# EVE4_L2_FNOC register map
Vendor: Texas Instruments
Peripheral module from a debugger description file (folder TDA2Px).
Registers are 32-bit, read-only, reset 0x0 unless marked. A register's access mark holds for its fields unless they carry their own. Offsets are as the file gives them; lines under a group give offsets from that group; [hi:lo] are bit positions; {n}, {i} and the like mark numbered series; 'fields as' and 'values as' point back to an identical list; <NAME> marks a mode.

## EVE4_L2_FNOC
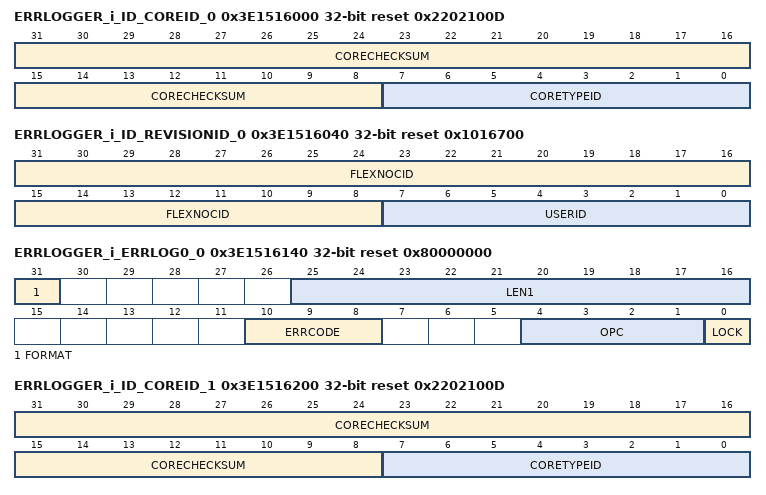
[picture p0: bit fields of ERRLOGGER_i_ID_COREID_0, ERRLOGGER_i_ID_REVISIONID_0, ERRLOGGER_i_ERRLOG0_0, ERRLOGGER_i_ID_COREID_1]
0x3E1516000 ERRLOGGER_i_ID_COREID_0 reset 0x2202100D
  [31:8] CORECHECKSUM — Field containing a checksum of the parameters of the IP.
  [7:0] CORETYPEID — Field identifying the type of IP.
0x3E1516040 ERRLOGGER_i_ID_REVISIONID_0 reset 0x1016700
  [31:8] FLEXNOCID — Field containing the build revision of the software used to generate the IP HDL code.
  [7:0] USERID — Field containing a user defined value, not used anywhere inside the IP itself.
0x3E1516080 ERRLOGGER_i_FAULTEN_0 access per field
  [0] FAULTEN rw — Enable Fault output
0x3E15160C0 ERRLOGGER_i_ERRVLD_0
  [0] ERRVLD — Error logged Valid
0x3E1516100 ERRLOGGER_i_ERRCLR_0 access per field
  [0] ERRCLR rw — Clr ErrVld status
0x3E1516140 ERRLOGGER_i_ERRLOG0_0 reset 0x80000000 — Header: Lock, Opcode, Len1, ErrCode values
  [31] FORMAT — Format of ErrLog0 register
  [25:16] LEN1 — Header: Len1 value
  [10:8] ERRCODE — Header: Error Code value
  [4:1] OPC — Header: Opcode value
  [0] LOCK — Header: Lock bit value
0x3E1516180 ERRLOGGER_i_ERRLOG1_0
  [13:0] ERRLOG1 — Header: RouteId lsb value
0x3E1516200 ERRLOGGER_i_ID_COREID_1 reset 0x2202100D
  fields as ERRLOGGER_i_ID_COREID_0
0x3E1516200 ERRLOGGER_i_ERRLOG3_0
  [31:0] ERRLOG3 — Header: Addr lsb value
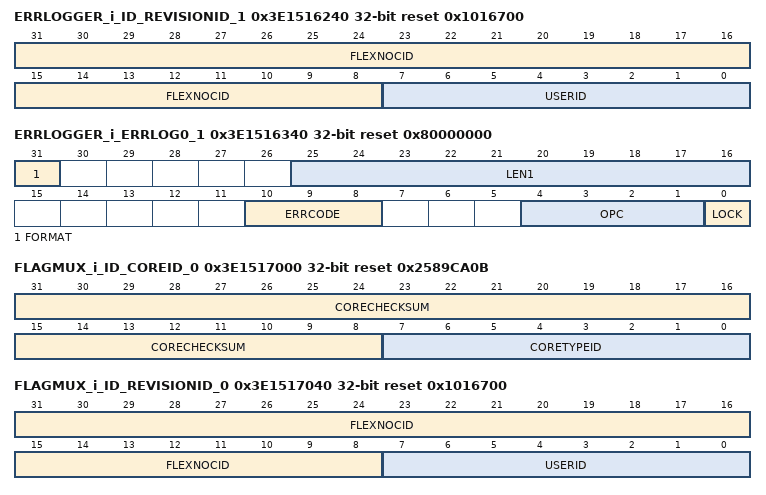
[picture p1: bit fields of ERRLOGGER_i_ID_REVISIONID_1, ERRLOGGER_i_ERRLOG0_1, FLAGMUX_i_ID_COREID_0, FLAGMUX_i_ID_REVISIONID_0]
0x3E1516240 ERRLOGGER_i_ID_REVISIONID_1 reset 0x1016700
  fields as ERRLOGGER_i_ID_REVISIONID_0
0x3E1516280 ERRLOGGER_i_FAULTEN_1 access per field
  [0] FAULTEN rw — Enable Fault output
0x3E1516280 ERRLOGGER_i_ERRLOG5_0
  [16:0] ERRLOG5 — Header: User lsb value
0x3E15162C0 ERRLOGGER_i_ERRVLD_1
  [0] ERRVLD — Error logged Valid
0x3E1516300 ERRLOGGER_i_ERRCLR_1 access per field
  [0] ERRCLR rw — Clr ErrVld status
0x3E1516340 ERRLOGGER_i_ERRLOG0_1 reset 0x80000000 — Header: Lock, Opcode, Len1, ErrCode values
  fields as ERRLOGGER_i_ERRLOG0_0
0x3E1516380 ERRLOGGER_i_ERRLOG1_1
  [13:0] ERRLOG1 — Header: RouteId lsb value
0x3E1516400 ERRLOGGER_i_ERRLOG3_1
  [31:0] ERRLOG3 — Header: Addr lsb value
0x3E1516480 ERRLOGGER_i_ERRLOG5_1
  [16:0] ERRLOG5 — Header: User lsb value
0x3E1517000 FLAGMUX_i_ID_COREID_0 reset 0x2589CA0B
  fields as ERRLOGGER_i_ID_COREID_0
0x3E1517040 FLAGMUX_i_ID_REVISIONID_0 reset 0x1016700
  fields as ERRLOGGER_i_ID_REVISIONID_0
0x3E1517080 FLAGMUX_i_FAULTEN_0 access per field
  [0] FAULTEN rw — Global Fault Enable register
0x3E15170C0 FLAGMUX_i_FAULTSTATUS_0
  [0] FAULTSTATUS — Global Fault Status register
0x3E1517100 FLAGMUX_i_FLAGINEN0_0 access per field
  [0] FLAGINEN0 rw — FlagIn Enable register #0
0x3E1517140 FLAGMUX_i_FLAGINSTATUS0_0
  [0] FLAGINSTATUS0 — FlagIn Status register #0
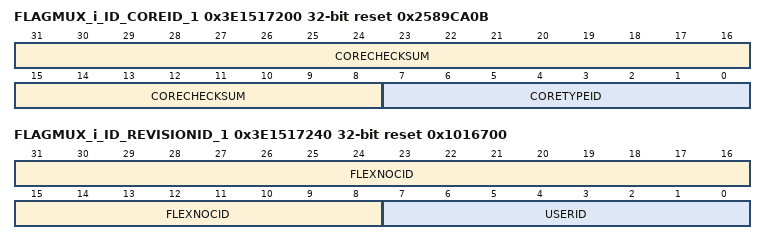
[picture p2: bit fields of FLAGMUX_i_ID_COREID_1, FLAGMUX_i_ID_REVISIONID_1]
0x3E1517200 FLAGMUX_i_ID_COREID_1 reset 0x2589CA0B
  fields as ERRLOGGER_i_ID_COREID_0
0x3E1517240 FLAGMUX_i_ID_REVISIONID_1 reset 0x1016700
  fields as ERRLOGGER_i_ID_REVISIONID_0
0x3E1517280 FLAGMUX_i_FAULTEN_1 access per field
  [0] FAULTEN rw — Global Fault Enable register
0x3E15172C0 FLAGMUX_i_FAULTSTATUS_1
  [0] FAULTSTATUS — Global Fault Status register
0x3E1517300 FLAGMUX_i_FLAGINEN0_1 access per field
  [0] FLAGINEN0 rw — FlagIn Enable register #0
0x3E1517340 FLAGMUX_i_FLAGINSTATUS0_1
  [0] FLAGINSTATUS0 — FlagIn Status register #0
